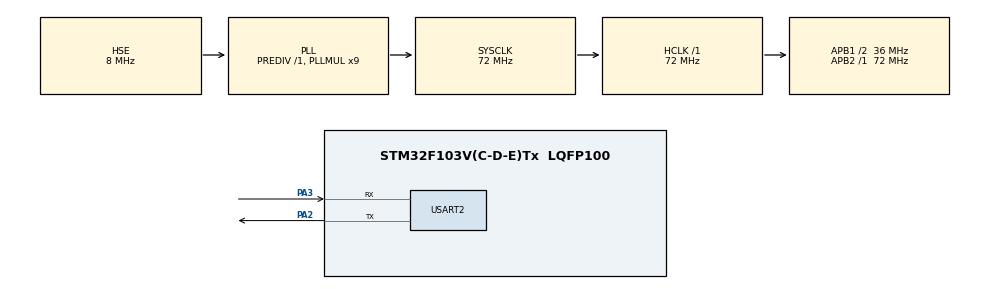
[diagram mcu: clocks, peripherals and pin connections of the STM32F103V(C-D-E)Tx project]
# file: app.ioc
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Mcu.Family=STM32F1
Mcu.Name=STM32F103V(C-D-E)Tx
Mcu.Package=LQFP100
NVIC.PriorityGroup=NVIC_PRIORITYGROUP_4
NVIC.USART2_IRQn=true\:0\:0\:false\:false\:true\:true
OSC_IN.Mode=HSE-External-Oscillator
OSC_IN.Signal=RCC_OSC_IN
OSC_OUT.Mode=HSE-External-Oscillator
OSC_OUT.Signal=RCC_OSC_OUT
PA13.Mode=Serial_Wire
PA13.Signal=SYS_JTMS-SWDIO
PA14.Mode=Serial_Wire
PA14.Signal=SYS_JTCK-SWCLK
PA2.Mode=Asynchronous
PA2.Signal=USART2_TX
PA3.Mode=Asynchronous
PA3.Signal=USART2_RX
PC14-OSC32_IN.Mode=LSE-External-Oscillator
PC14-OSC32_IN.Signal=RCC_OSC32_IN
PC15-OSC32_OUT.Mode=LSE-External-Oscillator
PC15-OSC32_OUT.Signal=RCC_OSC32_OUT
ProjectManager.HeapSize=0x200
ProjectManager.StackSize=0x400
ProjectManager.TargetToolchain=Makefile
RCC.AHBFreq_Value=72000000
RCC.APB1CLKDivider=RCC_HCLK_DIV2
RCC.APB1Freq_Value=36000000
RCC.APB1TimFreq_Value=72000000
RCC.APB2Freq_Value=72000000
RCC.APB2TimFreq_Value=72000000
RCC.HCLKFreq_Value=72000000
RCC.PLLMUL=RCC_PLL_MUL9
RCC.PLLSourceVirtual=RCC_PLLSOURCE_HSE
RCC.RTCClockSelection=RCC_RTCCLKSOURCE_LSE
RCC.SYSCLKFreq_VALUE=72000000
RCC.SYSCLKSource=RCC_SYSCLKSOURCE_PLLCLK
RCC.USBFreq_Value=72000000
USART2.VirtualMode=VM_ASYNC
VP_RTC_VS_RTC_Activate.Mode=RTC_Enabled
board=app

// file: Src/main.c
/**
  ******************************************************************************
  * @file           : main.c
  * @brief          : Main program body
  ******************************************************************************
  ** This notice applies to any and all portions of this file
  * that are not between comment pairs USER CODE BEGIN and
  * USER CODE END. Other portions of this file, whether
  * inserted by the user or by software development tools
  * are owned by their respective copyright owners.
  *
  * COPYRIGHT(c) 2018 STMicroelectronics
  *
  * Redistribution and use in source and binary forms, with or without modification,
  * are permitted provided that the following conditions are met:
  *   1. Redistributions of source code must retain the above copyright notice,
  *      this list of conditions and the following disclaimer.
  *   2. Redistributions in binary form must reproduce the above copyright notice,
  *      this list of conditions and the following disclaimer in the documentation
  *      and/or other materials provided with the distribution.
  *   3. Neither the name of STMicroelectronics nor the names of its contributors
  *      may be used to endorse or promote products derived from this software
  *      without specific prior written permission.
  *
  * THIS SOFTWARE IS PROVIDED BY THE COPYRIGHT HOLDERS AND CONTRIBUTORS "AS IS"
  * AND ANY EXPRESS OR IMPLIED WARRANTIES, INCLUDING, BUT NOT LIMITED TO, THE
  * IMPLIED WARRANTIES OF MERCHANTABILITY AND FITNESS FOR A PARTICULAR PURPOSE ARE
  * DISCLAIMED. IN NO EVENT SHALL THE COPYRIGHT HOLDER OR CONTRIBUTORS BE LIABLE
  * FOR ANY DIRECT, INDIRECT, INCIDENTAL, SPECIAL, EXEMPLARY, OR CONSEQUENTIAL
  * DAMAGES (INCLUDING, BUT NOT LIMITED TO, PROCUREMENT OF SUBSTITUTE GOODS OR
  * SERVICES; LOSS OF USE, DATA, OR PROFITS; OR BUSINESS INTERRUPTION) HOWEVER
  * CAUSED AND ON ANY THEORY OF LIABILITY, WHETHER IN CONTRACT, STRICT LIABILITY,
  * OR TORT (INCLUDING NEGLIGENCE OR OTHERWISE) ARISING IN ANY WAY OUT OF THE USE
  * OF THIS SOFTWARE, EVEN IF ADVISED OF THE POSSIBILITY OF SUCH DAMAGE.
  *
  ******************************************************************************
  */
#include "main.h"
#include "stm32f1xx_hal.h"

/* USER CODE BEGIN Includes */
#include "sim_util.h"
#include <stdio.h>
#include <stdlib.h>
/* USER CODE END Includes */

RTC_HandleTypeDef hrtc;

UART_HandleTypeDef huart2;

/* USER CODE BEGIN PV */
/* Private variables ---------------------------------------------------------*/

/* USER CODE END PV */

void SystemClock_Config(void);
static void MX_GPIO_Init(void);
static void MX_RTC_Init(void);
static void MX_USART2_UART_Init(void);

/* USER CODE BEGIN PFP */
/* Private function prototypes -----------------------------------------------*/

/* USER CODE END PFP */

int main(void)
{

  /* MCU Configuration----------------------------------------------------------*/

  /* Reset of all peripherals, Initializes the Flash interface and the Systick. */
  HAL_Init();

  /* Configure the system clock */
  SystemClock_Config();

  /* Initialize all configured peripherals */
  MX_GPIO_Init();
  MX_RTC_Init();
  MX_USART2_UART_Init();

  /* Infinite loop */
  /* USER CODE BEGIN WHILE */
  uint8_t* response = NULL;
  int8_t ret = sim_send_command("AT+CGMM\r\n",&response);
  if(!ret)
  {
    printf("%s",response);
  }
  while (1) {

  /* USER CODE END WHILE */

  }

}

void SystemClock_Config(void)
{

  RCC_OscInitTypeDef RCC_OscInitStruct;
  RCC_ClkInitTypeDef RCC_ClkInitStruct;
  RCC_PeriphCLKInitTypeDef PeriphClkInit;

    /**Initializes the CPU, AHB and APB busses clocks
    */
  RCC_OscInitStruct.OscillatorType = RCC_OSCILLATORTYPE_HSE|RCC_OSCILLATORTYPE_LSE;
  RCC_OscInitStruct.HSEState = RCC_HSE_ON;
  RCC_OscInitStruct.HSEPredivValue = RCC_HSE_PREDIV_DIV1;
  RCC_OscInitStruct.LSEState = RCC_LSE_ON;
  RCC_OscInitStruct.HSIState = RCC_HSI_ON;
  RCC_OscInitStruct.PLL.PLLState = RCC_PLL_ON;
  RCC_OscInitStruct.PLL.PLLSource = RCC_PLLSOURCE_HSE;
  RCC_OscInitStruct.PLL.PLLMUL = RCC_PLL_MUL9;
  if (HAL_RCC_OscConfig(&RCC_OscInitStruct) != HAL_OK)
  {
    _Error_Handler(__FILE__, __LINE__);
  }

    /**Initializes the CPU, AHB and APB busses clocks
    */
  RCC_ClkInitStruct.ClockType = RCC_CLOCKTYPE_HCLK|RCC_CLOCKTYPE_SYSCLK
                              |RCC_CLOCKTYPE_PCLK1|RCC_CLOCKTYPE_PCLK2;
  RCC_ClkInitStruct.SYSCLKSource = RCC_SYSCLKSOURCE_PLLCLK;
  RCC_ClkInitStruct.AHBCLKDivider = RCC_SYSCLK_DIV1;
  RCC_ClkInitStruct.APB1CLKDivider = RCC_HCLK_DIV2;
  RCC_ClkInitStruct.APB2CLKDivider = RCC_HCLK_DIV1;

  if (HAL_RCC_ClockConfig(&RCC_ClkInitStruct, FLASH_LATENCY_2) != HAL_OK)
  {
    _Error_Handler(__FILE__, __LINE__);
  }

  PeriphClkInit.PeriphClockSelection = RCC_PERIPHCLK_RTC;
  PeriphClkInit.RTCClockSelection = RCC_RTCCLKSOURCE_LSE;
  if (HAL_RCCEx_PeriphCLKConfig(&PeriphClkInit) != HAL_OK)
  {
    _Error_Handler(__FILE__, __LINE__);
  }

    /**Configure the Systick interrupt time
    */
  HAL_SYSTICK_Config(HAL_RCC_GetHCLKFreq()/1000);

    /**Configure the Systick
    */
  HAL_SYSTICK_CLKSourceConfig(SYSTICK_CLKSOURCE_HCLK);

  /* SysTick_IRQn interrupt configuration */
  HAL_NVIC_SetPriority(SysTick_IRQn, 0, 0);
}

/* RTC init function */
static void MX_RTC_Init(void)
{

    /**Initialize RTC Only
    */
  hrtc.Instance = RTC;
  hrtc.Init.AsynchPrediv = RTC_AUTO_1_SECOND;
  hrtc.Init.OutPut = RTC_OUTPUTSOURCE_ALARM;
  if (HAL_RTC_Init(&hrtc) != HAL_OK)
  {
    _Error_Handler(__FILE__, __LINE__);
  }

}

/* USART2 init function */
static void MX_USART2_UART_Init(void)
{

  huart2.Instance = USART2;
  huart2.Init.BaudRate = 115200;
  huart2.Init.WordLength = UART_WORDLENGTH_8B;
  huart2.Init.StopBits = UART_STOPBITS_1;
  huart2.Init.Parity = UART_PARITY_NONE;
  huart2.Init.Mode = UART_MODE_TX_RX;
  huart2.Init.HwFlowCtl = UART_HWCONTROL_NONE;
  huart2.Init.OverSampling = UART_OVERSAMPLING_16;
  if (HAL_UART_Init(&huart2) != HAL_OK)
  {
    _Error_Handler(__FILE__, __LINE__);
  }

}

/** Configure pins as
        * Analog
        * Input
        * Output
        * EVENT_OUT
        * EXTI
        * Free pins are configured automatically as Analog (this feature is enabled through
        * the Code Generation settings)
*/
static void MX_GPIO_Init(void)
{

  GPIO_InitTypeDef GPIO_InitStruct;

  /* GPIO Ports Clock Enable */
  __HAL_RCC_GPIOE_CLK_ENABLE();
  __HAL_RCC_GPIOC_CLK_ENABLE();
  __HAL_RCC_GPIOA_CLK_ENABLE();
  __HAL_RCC_GPIOB_CLK_ENABLE();
  __HAL_RCC_GPIOD_CLK_ENABLE();

  /*Configure GPIO pins : PE2 PE3 PE4 PE5
                           PE6 PE7 PE8 PE9
                           PE10 PE11 PE12 PE13
                           PE14 PE15 PE0 PE1 */
  GPIO_InitStruct.Pin = GPIO_PIN_2|GPIO_PIN_3|GPIO_PIN_4|GPIO_PIN_5
                          |GPIO_PIN_6|GPIO_PIN_7|GPIO_PIN_8|GPIO_PIN_9
                          |GPIO_PIN_10|GPIO_PIN_11|GPIO_PIN_12|GPIO_PIN_13
                          |GPIO_PIN_14|GPIO_PIN_15|GPIO_PIN_0|GPIO_PIN_1;
  GPIO_InitStruct.Mode = GPIO_MODE_ANALOG;
  HAL_GPIO_Init(GPIOE, &GPIO_InitStruct);

  /*Configure GPIO pins : PC13 PC0 PC1 PC2
                           PC3 PC4 PC5 PC6
                           PC7 PC8 PC9 PC10
                           PC11 PC12 */
  GPIO_InitStruct.Pin = GPIO_PIN_13|GPIO_PIN_0|GPIO_PIN_1|GPIO_PIN_2
                          |GPIO_PIN_3|GPIO_PIN_4|GPIO_PIN_5|GPIO_PIN_6
                          |GPIO_PIN_7|GPIO_PIN_8|GPIO_PIN_9|GPIO_PIN_10
                          |GPIO_PIN_11|GPIO_PIN_12;
  GPIO_InitStruct.Mode = GPIO_MODE_ANALOG;
  HAL_GPIO_Init(GPIOC, &GPIO_InitStruct);

  /*Configure GPIO pins : PA0 PA1 PA4 PA5
                           PA6 PA7 PA8 PA9
                           PA10 PA11 PA12 PA15 */
  GPIO_InitStruct.Pin = GPIO_PIN_0|GPIO_PIN_1|GPIO_PIN_4|GPIO_PIN_5
                          |GPIO_PIN_6|GPIO_PIN_7|GPIO_PIN_8|GPIO_PIN_9
                          |GPIO_PIN_10|GPIO_PIN_11|GPIO_PIN_12|GPIO_PIN_15;
  GPIO_InitStruct.Mode = GPIO_MODE_ANALOG;
  HAL_GPIO_Init(GPIOA, &GPIO_InitStruct);

  /*Configure GPIO pins : PB0 PB1 PB2 PB10
                           PB11 PB12 PB13 PB14
                           PB15 PB3 PB4 PB5
                           PB6 PB7 PB8 PB9 */
  GPIO_InitStruct.Pin = GPIO_PIN_0|GPIO_PIN_1|GPIO_PIN_2|GPIO_PIN_10
                          |GPIO_PIN_11|GPIO_PIN_12|GPIO_PIN_13|GPIO_PIN_14
                          |GPIO_PIN_15|GPIO_PIN_3|GPIO_PIN_4|GPIO_PIN_5
                          |GPIO_PIN_6|GPIO_PIN_7|GPIO_PIN_8|GPIO_PIN_9;
  GPIO_InitStruct.Mode = GPIO_MODE_ANALOG;
  HAL_GPIO_Init(GPIOB, &GPIO_InitStruct);

  /*Configure GPIO pins : PD8 PD9 PD10 PD11
                           PD12 PD13 PD14 PD15
                           PD0 PD1 PD2 PD3
                           PD4 PD5 PD6 PD7 */
  GPIO_InitStruct.Pin = GPIO_PIN_8|GPIO_PIN_9|GPIO_PIN_10|GPIO_PIN_11
                          |GPIO_PIN_12|GPIO_PIN_13|GPIO_PIN_14|GPIO_PIN_15
                          |GPIO_PIN_0|GPIO_PIN_1|GPIO_PIN_2|GPIO_PIN_3
                          |GPIO_PIN_4|GPIO_PIN_5|GPIO_PIN_6|GPIO_PIN_7;
  GPIO_InitStruct.Mode = GPIO_MODE_ANALOG;
  HAL_GPIO_Init(GPIOD, &GPIO_InitStruct);

}

void _Error_Handler(char *file, int line)
{
  while (1) {
  }
}

/************************ (C) COPYRIGHT STMicroelectronics *****END OF FILE****/
